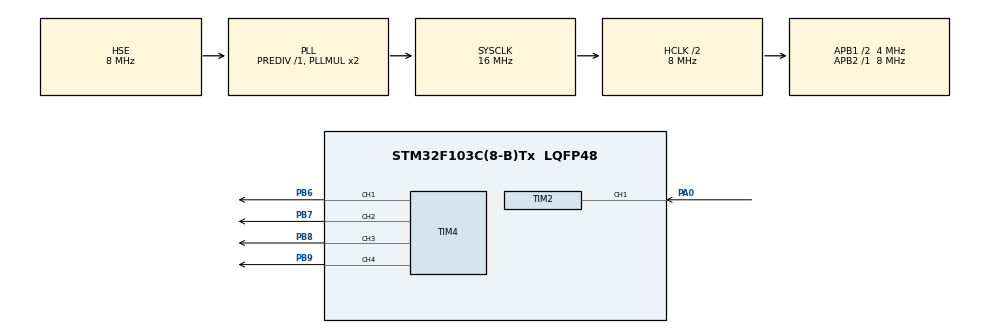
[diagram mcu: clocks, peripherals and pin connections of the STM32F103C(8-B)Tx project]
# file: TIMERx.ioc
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Mcu.Family=STM32F1
Mcu.Name=STM32F103C(8-B)Tx
Mcu.Package=LQFP48
NVIC.PriorityGroup=NVIC_PRIORITYGROUP_4
PA0-WKUP.Signal=S_TIM2_CH1_ETR
PA13.Mode=Serial_Wire
PA13.Signal=SYS_JTMS-SWDIO
PA14.Mode=Serial_Wire
PA14.Signal=SYS_JTCK-SWCLK
PB6.Signal=S_TIM4_CH1
PB7.Signal=S_TIM4_CH2
PB8.Signal=S_TIM4_CH3
PB9.Signal=S_TIM4_CH4
PD0-OSC_IN.Mode=HSE-External-Oscillator
PD0-OSC_IN.Signal=RCC_OSC_IN
PD1-OSC_OUT.Mode=HSE-External-Oscillator
PD1-OSC_OUT.Signal=RCC_OSC_OUT
ProjectManager.HeapSize=0x200
ProjectManager.StackSize=0x400
ProjectManager.TargetToolchain=STM32CubeIDE
RCC.AHBCLKDivider=RCC_SYSCLK_DIV2
RCC.AHBFreq_Value=8000000
RCC.APB1CLKDivider=RCC_HCLK_DIV2
RCC.APB1Freq_Value=4000000
RCC.APB1TimFreq_Value=8000000
RCC.APB2Freq_Value=8000000
RCC.APB2TimFreq_Value=8000000
RCC.HCLKFreq_Value=8000000
RCC.PLLSourceVirtual=RCC_PLLSOURCE_HSE
RCC.SYSCLKFreq_VALUE=16000000
RCC.SYSCLKSource=RCC_SYSCLKSOURCE_PLLCLK
RCC.USBFreq_Value=16000000
SH.S_TIM2_CH1_ETR.0=TIM2_CH1,Input_Capture1_from_TI1
SH.S_TIM4_CH1.0=TIM4_CH1,Output Compare1 CH1
SH.S_TIM4_CH2.0=TIM4_CH2,Output Compare2 CH2
SH.S_TIM4_CH3.0=TIM4_CH3,Output Compare3 CH3
SH.S_TIM4_CH4.0=TIM4_CH4,Output Compare4 CH4
TIM2.Channel-Input_Capture1_from_TI1=TIM_CHANNEL_1
TIM4.Channel-Output\ Compare1\ CH1=TIM_CHANNEL_1
TIM4.Channel-Output\ Compare2\ CH2=TIM_CHANNEL_2
TIM4.Channel-Output\ Compare3\ CH3=TIM_CHANNEL_3
TIM4.Channel-Output\ Compare4\ CH4=TIM_CHANNEL_4
board=custom

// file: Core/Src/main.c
/* USER CODE BEGIN Header */
/**
  ******************************************************************************
  * @file           : main.c
  * @brief          : Main program body
  ******************************************************************************
  * @attention
  *
  * Copyright (c) 2026 STMicroelectronics.
  * All rights reserved.
  *
  * This software is licensed under terms that can be found in the LICENSE file
  * in the root directory of this software component.
  * If no LICENSE file comes with this software, it is provided AS-IS.
  *
  ******************************************************************************
  */
/* USER CODE END Header */
#include "main.h"
#include "timer.h"
#include "pwm.h"
#include "capture.h"

TIM_HandleTypeDef htim2;
TIM_HandleTypeDef htim4;

/* USER CODE BEGIN PV */
uint32_t t_pwm = 0;
uint32_t pulse_width1 = 0;
uint32_t pulse_width2 = 0;
uint32_t pulse_width3 = 0;

/* USER CODE END PV */

void SystemClock_Config(void);
static void MX_GPIO_Init(void);
static void MX_TIM4_Init(void);
static void MX_TIM2_Init(void);

int main(void)
{

  /* MCU Configuration--------------------------------------------------------*/

  /* Reset of all peripherals, Initializes the Flash interface and the Systick. */
  HAL_Init();

  /* Configure the system clock */
  SystemClock_Config();

  /* Initialize all configured peripherals */
  MX_GPIO_Init();
  MX_TIM4_Init();
  MX_TIM2_Init();
  /* USER CODE BEGIN 2 */

  capture_init();   // Khởi động Input Capture trên TIM2_CH1 (đọc xung từ TIM4_CH1)
  PWM_init();       // Khởi động PWM trên TIM4_CH1
  /* USER CODE END 2 */

  /* Infinite loop */
  /* USER CODE BEGIN WHILE */
  while (1)
  {
    t_pwm = capture_read();
    pulse_width1 = capture_pulse_width1();
    pulse_width2 = capture_pulse_width2();
    pulse_width3 = capture_pulse_width3();
    HAL_Delay(500);

    /* USER CODE END WHILE */

  }
}

void SystemClock_Config(void)
{
  RCC_OscInitTypeDef RCC_OscInitStruct = {0};
  RCC_ClkInitTypeDef RCC_ClkInitStruct = {0};

  /** Initializes the RCC Oscillators according to the specified parameters
  * in the RCC_OscInitTypeDef structure.
  */
  RCC_OscInitStruct.OscillatorType = RCC_OSCILLATORTYPE_HSE;
  RCC_OscInitStruct.HSEState = RCC_HSE_ON;
  RCC_OscInitStruct.HSEPredivValue = RCC_HSE_PREDIV_DIV1;
  RCC_OscInitStruct.HSIState = RCC_HSI_ON;
  RCC_OscInitStruct.PLL.PLLState = RCC_PLL_ON;
  RCC_OscInitStruct.PLL.PLLSource = RCC_PLLSOURCE_HSE;
  RCC_OscInitStruct.PLL.PLLMUL = RCC_PLL_MUL2;
  if (HAL_RCC_OscConfig(&RCC_OscInitStruct) != HAL_OK)
  {
    Error_Handler();
  }

  /** Initializes the CPU, AHB and APB buses clocks
  */
  RCC_ClkInitStruct.ClockType = RCC_CLOCKTYPE_HCLK|RCC_CLOCKTYPE_SYSCLK
                              |RCC_CLOCKTYPE_PCLK1|RCC_CLOCKTYPE_PCLK2;
  RCC_ClkInitStruct.SYSCLKSource = RCC_SYSCLKSOURCE_PLLCLK;
  RCC_ClkInitStruct.AHBCLKDivider = RCC_SYSCLK_DIV2;
  RCC_ClkInitStruct.APB1CLKDivider = RCC_HCLK_DIV2;
  RCC_ClkInitStruct.APB2CLKDivider = RCC_HCLK_DIV1;

  if (HAL_RCC_ClockConfig(&RCC_ClkInitStruct, FLASH_LATENCY_0) != HAL_OK)
  {
    Error_Handler();
  }
}

static void MX_TIM2_Init(void)
{

  TIM_MasterConfigTypeDef sMasterConfig = {0};
  TIM_IC_InitTypeDef sConfigIC = {0};

  htim2.Instance = TIM2;
  htim2.Init.Prescaler = 0;
  htim2.Init.CounterMode = TIM_COUNTERMODE_UP;
  htim2.Init.Period = 65535;
  htim2.Init.ClockDivision = TIM_CLOCKDIVISION_DIV1;
  htim2.Init.AutoReloadPreload = TIM_AUTORELOAD_PRELOAD_DISABLE;
  if (HAL_TIM_IC_Init(&htim2) != HAL_OK)
  {
    Error_Handler();
  }
  sMasterConfig.MasterOutputTrigger = TIM_TRGO_RESET;
  sMasterConfig.MasterSlaveMode = TIM_MASTERSLAVEMODE_DISABLE;
  if (HAL_TIMEx_MasterConfigSynchronization(&htim2, &sMasterConfig) != HAL_OK)
  {
    Error_Handler();
  }
  sConfigIC.ICPolarity = TIM_INPUTCHANNELPOLARITY_RISING;
  sConfigIC.ICSelection = TIM_ICSELECTION_DIRECTTI;
  sConfigIC.ICPrescaler = TIM_ICPSC_DIV1;
  sConfigIC.ICFilter = 0;
  if (HAL_TIM_IC_ConfigChannel(&htim2, &sConfigIC, TIM_CHANNEL_1) != HAL_OK)
  {
    Error_Handler();
  }

}

static void MX_TIM4_Init(void)
{

  TIM_MasterConfigTypeDef sMasterConfig = {0};
  TIM_OC_InitTypeDef sConfigOC = {0};

  htim4.Instance = TIM4;
  htim4.Init.Prescaler = 0;
  htim4.Init.CounterMode = TIM_COUNTERMODE_UP;
  htim4.Init.Period = 65535;
  htim4.Init.ClockDivision = TIM_CLOCKDIVISION_DIV1;
  htim4.Init.AutoReloadPreload = TIM_AUTORELOAD_PRELOAD_DISABLE;
  if (HAL_TIM_OC_Init(&htim4) != HAL_OK)
  {
    Error_Handler();
  }
  sMasterConfig.MasterOutputTrigger = TIM_TRGO_RESET;
  sMasterConfig.MasterSlaveMode = TIM_MASTERSLAVEMODE_DISABLE;
  if (HAL_TIMEx_MasterConfigSynchronization(&htim4, &sMasterConfig) != HAL_OK)
  {
    Error_Handler();
  }
  sConfigOC.OCMode = TIM_OCMODE_TIMING;
  sConfigOC.Pulse = 0;
  sConfigOC.OCPolarity = TIM_OCPOLARITY_HIGH;
  sConfigOC.OCFastMode = TIM_OCFAST_DISABLE;
  if (HAL_TIM_OC_ConfigChannel(&htim4, &sConfigOC, TIM_CHANNEL_1) != HAL_OK)
  {
    Error_Handler();
  }
  if (HAL_TIM_OC_ConfigChannel(&htim4, &sConfigOC, TIM_CHANNEL_2) != HAL_OK)
  {
    Error_Handler();
  }
  if (HAL_TIM_OC_ConfigChannel(&htim4, &sConfigOC, TIM_CHANNEL_3) != HAL_OK)
  {
    Error_Handler();
  }
  if (HAL_TIM_OC_ConfigChannel(&htim4, &sConfigOC, TIM_CHANNEL_4) != HAL_OK)
  {
    Error_Handler();
  }
  HAL_TIM_MspPostInit(&htim4);

}

static void MX_GPIO_Init(void)
{

  /* GPIO Ports Clock Enable */
  __HAL_RCC_GPIOD_CLK_ENABLE();
  __HAL_RCC_GPIOA_CLK_ENABLE();
  __HAL_RCC_GPIOB_CLK_ENABLE();

  /* USER CODE BEGIN MX_GPIO_Init_2 */
  /* PA0 (TIM2_CH1) được cấu hình input floating bằng thanh ghi trực tiếp
   * trong capture_init() (file capture.c), không cấu hình lại ở đây. */
  /* USER CODE END MX_GPIO_Init_2 */
}

void Error_Handler(void)
{
  __disable_irq();
  while (1)
  {
  }
}
